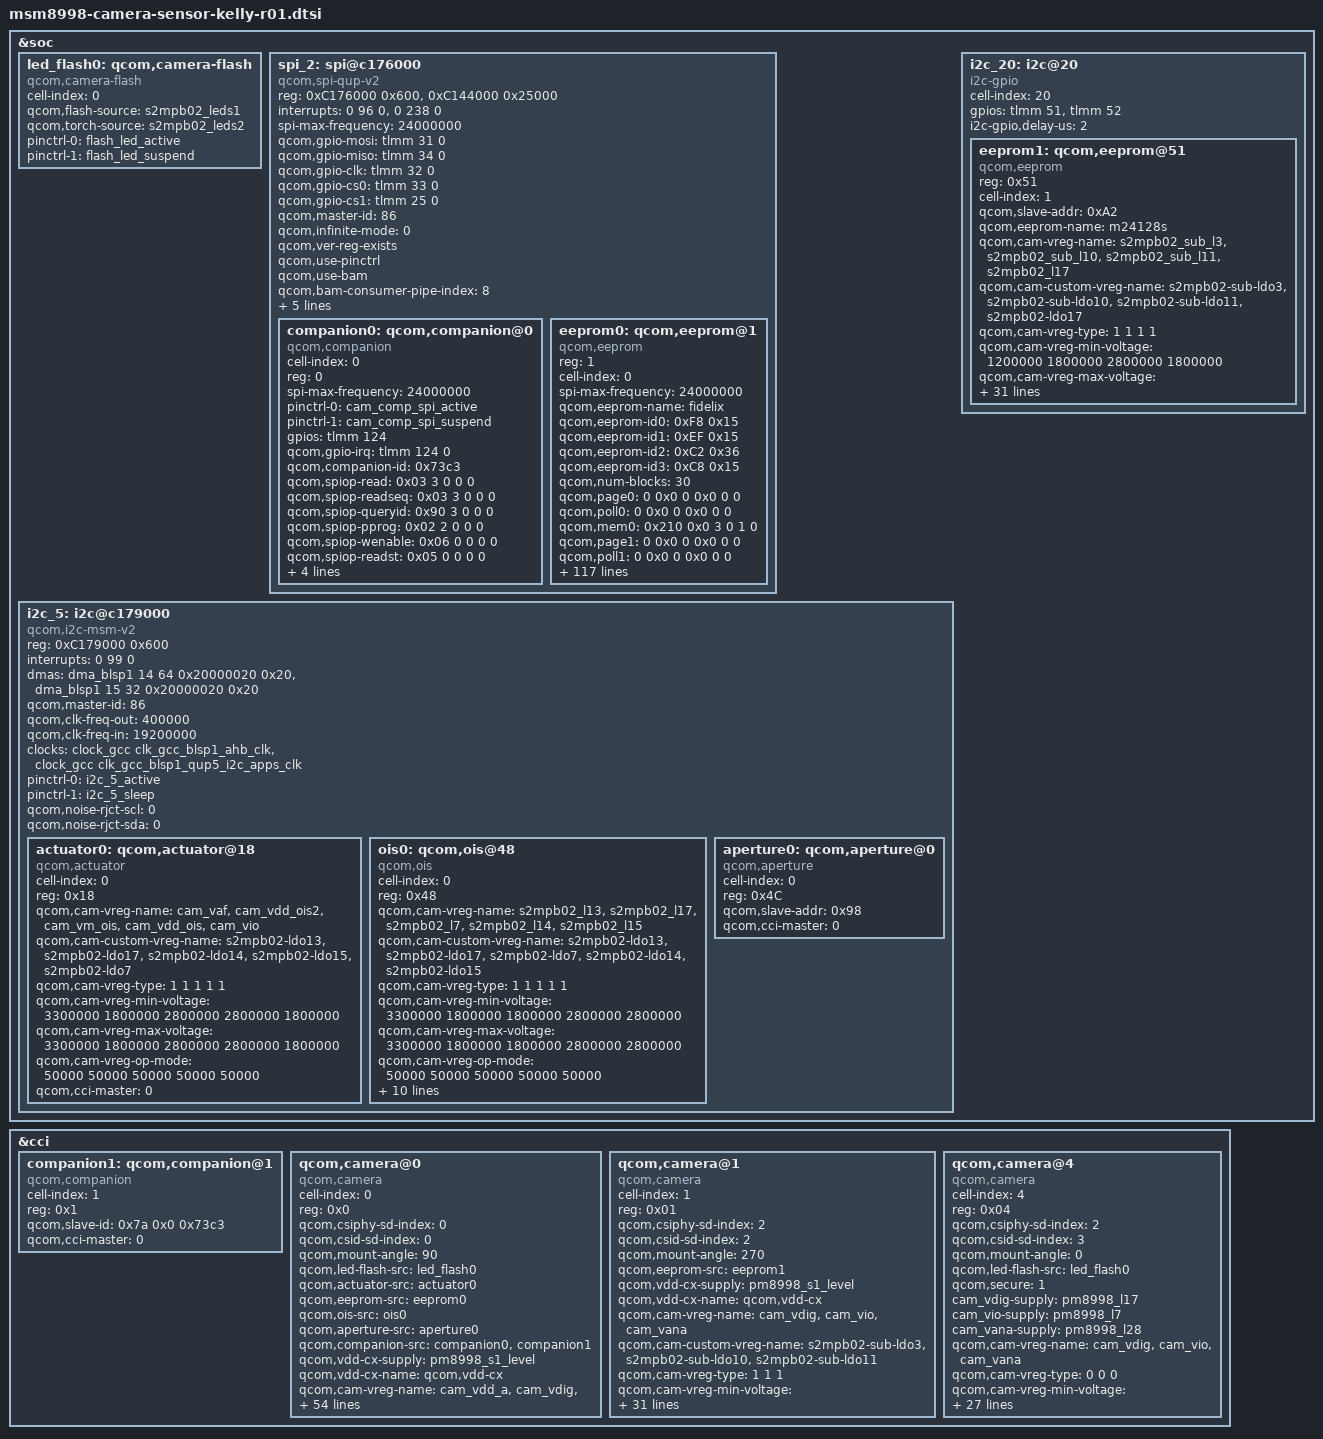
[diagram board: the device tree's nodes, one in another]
/*
 * Copyright (c) 2015 The Linux Foundation. All rights reserved.
 *
 * This program is free software; you can redistribute it and/or modify
 * it under the terms of the GNU General Public License version 2 and
 * only version 2 as published by the Free Software Foundation.
 *
 * This program is distributed in the hope that it will be useful,
 * but WITHOUT ANY WARRANTY; without even the implied warranty of
 * MERCHANTABILITY or FITNESS FOR A PARTICULAR PURPOSE.  See the
 * GNU General Public License for more details.
 */

&soc {
	led_flash0: qcom,camera-flash {
		cell-index = <0>;
		compatible = "qcom,camera-flash";
		qcom,flash-source = <&s2mpb02_leds1>;
		qcom,torch-source = <&s2mpb02_leds2>;
		pinctrl-names = "flash_default", "flash_suspend";
		pinctrl-0 = <&flash_led_active>;
		pinctrl-1 = <&flash_led_suspend>;
	};
};

&soc {
	spi_2: spi@c176000 {
		compatible = "qcom,spi-qup-v2";

		reg-names = "spi_physical", "spi_bam_physical";
		reg = <0xC176000 0x600>, <0xC144000 0x25000>;
		interrupt-names = "spi_irq", "spi_bam_irq";
		interrupts = <0 96 0>, <0 238 0>;

		spi-max-frequency = <24000000>;
		#address-cells = <1>;
		#size-cells = <0>;

		qcom,gpio-mosi = <&tlmm 31 0>;
		qcom,gpio-miso = <&tlmm 34 0>;
		qcom,gpio-clk  = <&tlmm 32 0>;
		qcom,gpio-cs0  = <&tlmm 33 0>;
		qcom,gpio-cs1  = <&tlmm 25 0>;

		qcom,master-id = <86>;
		qcom,infinite-mode = <0>;
		qcom,ver-reg-exists;
		qcom,use-pinctrl;
		qcom,use-bam;
		qcom,bam-consumer-pipe-index = <8>;
		qcom,bam-producer-pipe-index = <9>;
		pinctrl-names = "spi_default", "spi_sleep";
		pinctrl-0 = <&spi_2_active &spi_2_cs1_active>;
		pinctrl-1 = <&spi_2_sleep &spi_2_cs1_sleep>;
		status = "ok";

		clock-names = "iface_clk", "core_clk";

		clocks = <&clock_gcc clk_gcc_blsp1_ahb_clk>,
			 <&clock_gcc clk_gcc_blsp1_qup2_spi_apps_clk>;
	};

	i2c_5: i2c@c179000 {
		compatible = "qcom,i2c-msm-v2";
		#address-cells = <1>;
		#size-cells = <0>;
		reg-names = "qup_phys_addr";
		reg = <0xC179000 0x600>;
		interrupt-names = "qup_irq";
		interrupts = <0 99 0>;
		dmas = <&dma_blsp1 14 64 0x20000020 0x20>,
			<&dma_blsp1 15 32 0x20000020 0x20>;
		dma-names = "tx", "rx";
		qcom,master-id = <86>;
		qcom,clk-freq-out = <400000>;
		qcom,clk-freq-in  = <19200000>;
		clock-names = "iface_clk", "core_clk";
		clocks = <&clock_gcc clk_gcc_blsp1_ahb_clk>,
			<&clock_gcc clk_gcc_blsp1_qup5_i2c_apps_clk>;
		pinctrl-names = "i2c_active", "i2c_sleep";
		pinctrl-0 = <&i2c_5_active>;
		pinctrl-1 = <&i2c_5_sleep>;
		qcom,noise-rjct-scl = <0>;
		qcom,noise-rjct-sda = <0>;
		status = "ok";
	};

};

&i2c_5 {
	actuator0: qcom,actuator@18 {
		compatible = "qcom,actuator";
		cell-index = <0>;
		reg = <0x18>;
		qcom,cam-vreg-name = "cam_vaf", "cam_vdd_ois2", "cam_vm_ois", "cam_vdd_ois", "cam_vio";
		qcom,cam-custom-vreg-name = "s2mpb02-ldo13", "s2mpb02-ldo17", "s2mpb02-ldo14", "s2mpb02-ldo15", "s2mpb02-ldo7";
		qcom,cam-vreg-type = <1 1 1 1 1>;
		qcom,cam-vreg-min-voltage = <3300000 1800000 2800000 2800000 1800000>;
		qcom,cam-vreg-max-voltage = <3300000 1800000 2800000 2800000 1800000>;
		qcom,cam-vreg-op-mode = <50000 50000 50000 50000 50000>;
		qcom,cci-master = <0>;
		status = "ok";
	};

	ois0: qcom,ois@48  {
		compatible = "qcom,ois";
		cell-index = <0>;
		reg = <0x48>;
		qcom,cam-vreg-name = "s2mpb02_l13", "s2mpb02_l17", "s2mpb02_l7", "s2mpb02_l14", "s2mpb02_l15";
		qcom,cam-custom-vreg-name = "s2mpb02-ldo13", "s2mpb02-ldo17","s2mpb02-ldo7", "s2mpb02-ldo14", "s2mpb02-ldo15";
		qcom,cam-vreg-type = <1 1 1 1 1>;
		qcom,cam-vreg-min-voltage = <3300000 1800000 1800000 2800000 2800000>;
		qcom,cam-vreg-max-voltage = <3300000 1800000 1800000 2800000 2800000>;
		qcom,cam-vreg-op-mode = <50000 50000 50000 50000 50000>;
		qcom,cci-master = <0>;
		gpios = <&tlmm 30 0>; /* RESET */
		qcom,gpio-reset = <0>;
		qcom,gpio-req-tbl-num = <0>;
		qcom,gpio-req-tbl-flags = <0>;
		qcom,gpio-req-tbl-label = "CAM_RESET0";
		qcom,gpio-set-tbl-delay = <1000>;
               clocks = <&clock_mmss clk_mclk0_clk_src>,
			<&clock_mmss clk_mmss_camss_mclk0_clk>;
		clock-names = "cam_src_clk", "cam_clk";
		qcom,clock-rates = <24000000 0>;
		status = "ok";
	};

	aperture0: qcom,aperture@0 {
		compatible = "qcom,aperture";
		cell-index = <0>;
		reg = <0x4C>;
		qcom,slave-addr = <0x98>;
		qcom,cci-master = <0>;
		status = "ok";
	};
};

&soc {
	i2c_20: i2c@20 {
		cell-index = <20>;
		compatible = "i2c-gpio";
		gpios = <&tlmm 51 0 // SDA
			&tlmm 52 0 // SCL
			>;
		i2c-gpio,delay-us = <2>;
		#address-cells = <1>;
		#size-cells = <0>;

		eeprom1: qcom,eeprom@51 {
			compatible = "qcom,eeprom";
			reg = <0x51>;
			cell-index = <1>;
			qcom,slave-addr = <0xA2>;
			qcom,eeprom-name = "m24128s";
			qcom,cam-vreg-name = "s2mpb02_sub_l3", "s2mpb02_sub_l10", "s2mpb02_sub_l11", "s2mpb02_l17";
			qcom,cam-custom-vreg-name = "s2mpb02-sub-ldo3", "s2mpb02-sub-ldo10", "s2mpb02-sub-ldo11", "s2mpb02-ldo17";
			qcom,cam-vreg-type = <1 1 1 1>;
			qcom,cam-vreg-min-voltage = <1200000 1800000 2800000 1800000>;
			qcom,cam-vreg-max-voltage = <1200000 1800000 2800000 1800000>;
			qcom,cam-vreg-op-mode = <200000 200000 200000 200000>;
			qcom,cam-power-seq-type = "sensor_vreg", "sensor_vreg", "sensor_vreg", "sensor_vreg";
			qcom,cam-power-seq-val = "s2mpb02_sub_l3", "s2mpb02_sub_l10", "s2mpb02_sub_l11", "s2mpb02_l17";
			qcom,cam-power-seq-cfg-val = <1 1 1 1>;
			qcom,cam-power-seq-delay =   <0 0 0 0>;
			qcom,sensor-position = <1>;
			qcom,num-blocks = <6>;
			qcom,page0 = <0 0x0 0 0x0 0 0>;
			qcom,poll0 = <0 0x0 0 0x0 0 0>;
			qcom,mem0 = <0xC0 0x0 2 0 1 0>;
			qcom,page1 = <0 0x0 0 0x0 0 0>;
			qcom,poll1 = <0 0x0 0 0x0 0 0>;
			qcom,mem1 = <0x4 0xFC 2 0 1 0>;
			qcom,page2 = <0 0x0 0 0x0 0 0>;
			qcom,poll2 = <0 0x0 0 0x0 0 0>;
			qcom,mem2 = <0x20 0x200 2 0 1 0>;
			qcom,page3 = <0 0x0 0 0x0 0 0>;
			qcom,poll3 = <0 0x0 0 0x0 0 0>;
			qcom,mem3 = <0x4 0x2FC 2 0 1 0>;
			qcom,page4 = <0 0x0 0 0x0 0 0>;
			qcom,poll4 = <0 0x0 0 0x0 0 0>;
			qcom,mem4 = <0x700 0x300 2 0 1 0>;
			qcom,page5 = <0 0x0 0 0x0 0 0>;
			qcom,poll5 = <0 0x0 0 0x0 0 0>;
			qcom,mem5 = <0x4 0xAFC 2 0 1 0>;
			qcom,total-size = <0xB00>;
			status = "ok";
		};
	};
};

&spi_2 {
	companion0: qcom,companion@0 {
		compatible = "qcom,companion";
		cell-index = <0>;
		reg = <0>;
		spi-max-frequency = <24000000>;
		pinctrl-names = "cam_default", "cam_suspend";
		pinctrl-0 = <&cam_comp_spi_active>;
		pinctrl-1 = <&cam_comp_spi_suspend>;
		status = "ok";
		gpios = <&tlmm 124 0>; /* COMP_PAF_INT */
		qcom,gpio-irq = <&tlmm 124 0>;
		qcom,companion-id = <0x73c3>;
		qcom,spiop-read = <0x03 3 0 0 0>;
		qcom,spiop-readseq = <0x03 3 0 0 0>;
		qcom,spiop-queryid = <0x90 3 0 0 0>;
		qcom,spiop-pprog = <0x02 2 0 0 0>;
		qcom,spiop-wenable = <0x06 0 0 0 0>;
		qcom,spiop-readst = <0x05 0 0 0 0>;
		qcom,spiop-erase = <0x20 2 0 10 30>;
		qcom,spi-busy-mask = <0x01>;
		qcom,spi-page-size = <0x256>;
		qcom,spi-erase-size = <0x4096>;
	};

	eeprom0: qcom,eeprom@1 {
		compatible = "qcom,eeprom";
		reg = <1>;
		cell-index = <0>;
		spi-max-frequency = <24000000>;
		status = "ok";

		qcom,eeprom-name = "fidelix";
		qcom,eeprom-id0 = <0xF8 0x15>;
		qcom,eeprom-id1 = <0xEF 0x15>;
		qcom,eeprom-id2 = <0xC2 0x36>;
		qcom,eeprom-id3 = <0xC8 0x15>;

		qcom,num-blocks = <30>;
		qcom,page0 = <0 0x0 0 0x0 0 0>;
		qcom,poll0 = <0 0x0 0 0x0 0 0>;
		qcom,mem0 = <0x210 0x0 3 0 1 0>;
		qcom,page1 = <0 0x0 0 0x0 0 0>;
		qcom,poll1 = <0 0x0 0 0x0 0 0>;
		qcom,mem1 = <0x4 0xFFC 3 0 1 0>;
		qcom,page2 = <0 0x0 0 0x0 0 0>;
		qcom,poll2 = <0 0x0 0 0x0 0 0>;
		qcom,mem2 = <0x16F8 0x1006 3 0 0 0>;
		qcom,page3 = <0 0x0 0 0x0 0 0>;
		qcom,poll3 = <0 0x0 0 0x0 0 0>;
		qcom,mem3 = <0x4 0x26FE 3 0 0 0>;
		qcom,page4 = <0 0x0 0 0x0 0 0>;
		qcom,poll4 = <0 0x0 0 0x0 0 0>;
		qcom,mem4 = <0xE4 0x2702 3 0 0 0>;
		qcom,page5 = <0 0x0 0 0x0 0 0>;
		qcom,poll5 = <0 0x0 0 0x0 0 0>;
		qcom,mem5 = <0x4 0x27E6 3 0 0 0>;
		qcom,page6 = <0 0x0 0 0x0 0 0>;
		qcom,poll6 = <0 0x0 0 0x0 0 0>;
		qcom,mem6 = <0x1000 0x27F0 3 0 0 0>;
		qcom,page7 = <0 0x0 0 0x0 0 0>;
		qcom,poll7 = <0 0x0 0 0x0 0 0>;
		qcom,mem7 = <0x4 0x37F0 3 0 0 0>;
		qcom,page8 = <0 0x0 0 0x0 0 0>;
		qcom,poll8 = <0 0x0 0 0x0 0 0>;
		qcom,mem8 = <0x420 0x37F4 3 0 0 0>;
		qcom,page9 = <0 0x0 0 0x0 0 0>;
		qcom,poll9 = <0 0x0 0 0x0 0 0>;
		qcom,mem9 = <0x4 0x3C14 3 0 0 0>;
		qcom,page10 = <0 0x0 0 0x0 0 0>;
		qcom,poll10 = <0 0x0 0 0x0 0 0>;
		qcom,mem10 = <0x16F8 0x3C26 3 0 0 0>;
		qcom,page11 = <0 0x0 0 0x0 0 0>;
		qcom,poll11 = <0 0x0 0 0x0 0 0>;
		qcom,mem11 = <0x4 0x531E 3 0 0 0>;
		qcom,page12 = <0 0x0 0 0x0 0 0>;
		qcom,poll12 = <0 0x0 0 0x0 0 0>;
		qcom,mem12 = <0xE4 0x5322 3 0 0 0>;
		qcom,page13 = <0 0x0 0 0x0 0 0>;
		qcom,poll13 = <0 0x0 0 0x0 0 0>;
		qcom,mem13 = <0x4 0x5406 3 0 0 0>;
		qcom,page14 = <0 0x0 0 0x0 0 0>;
		qcom,poll14 = <0 0x0 0 0x0 0 0>;
		qcom,mem14 = <0x1000 0x5410 3 0 0 0>;
		qcom,page15 = <0 0x0 0 0x0 0 0>;
		qcom,poll15 = <0 0x0 0 0x0 0 0>;
		qcom,mem15 = <0x4 0x6410 3 0 0 0>;
		qcom,page16 = <0 0x0 0 0x0 0 0>;
		qcom,poll16 = <0 0x0 0 0x0 0 0>;
		qcom,mem16 = <0x420 0x6414 3 0 0 0>;
		qcom,page17 = <0 0x0 0 0x0 0 0>;
		qcom,poll17 = <0 0x0 0 0x0 0 0>;
		qcom,mem17 = <0x4 0x6834 3 0 0 0>;
		qcom,page18 = <0 0x0 0 0x0 0 0>;
		qcom,poll18 = <0 0x0 0 0x0 0 0>;
		qcom,mem18 = <0x2C 0x6840 3 0 0 0>;
		qcom,page19 = <0 0x0 0 0x0 0 0>;
		qcom,poll19 = <0 0x0 0 0x0 0 0>;
		qcom,mem19 = <0x4 0x686C 3 0 0 0>;
		qcom,page20 = <0 0x0 0 0x0 0 0>;
		qcom,poll20 = <0 0x0 0 0x0 0 0>;
		qcom,mem20 = <0x7C 0x6870 3 0 0 0>;
		qcom,page21 = <0 0x0 0 0x0 0 0>;
		qcom,poll21 = <0 0x0 0 0x0 0 0>;
		qcom,mem21 = <0x4 0x68EC 3 0 0 0>;
		qcom,page22 = <0 0x0 0 0x0 0 0>;
		qcom,poll22 = <0 0x0 0 0x0 0 0>;
		qcom,mem22 = <0x6C 0x68F0 3 0 0 0>;
		qcom,page23 = <0 0x0 0 0x0 0 0>;
		qcom,poll23 = <0 0x0 0 0x0 0 0>;
		qcom,mem23 = <0x4 0x695C 3 0 0 0>;
		qcom,page24 = <0 0x0 0 0x0 0 0>;
		qcom,poll24 = <0 0x0 0 0x0 0 0>;
		qcom,mem24 = <0x45C 0x6960 3 0 0 0>;
		qcom,page25 = <0 0x0 0 0x0 0 0>;
		qcom,poll25 = <0 0x0 0 0x0 0 0>;
		qcom,mem25 = <0x4 0x6DBC 3 0 0 0>;
		qcom,page26 = <0 0x0 0 0x0 0 0>;
		qcom,poll26 = <0 0x0 0 0x0 0 0>;
		qcom,mem26 = <0x45C 0x6DC0 3 0 0 0>;
		qcom,page27 = <0 0x0 0 0x0 0 0>;
		qcom,poll27 = <0 0x0 0 0x0 0 0>;
		qcom,mem27 = <0x4 0x721C 3 0 0 0>;
		qcom,page28 = <0 0x0 0 0x0 0 0>;
		qcom,poll28 = <0 0x0 0 0x0 0 0>;
		qcom,mem28 = <0x6220 0x1000 3 0 1 0>;
		qcom,page29 = <0 0x0 0 0x0 0 0>;
		qcom,poll29 = <0 0x0 0 0x0 0 0>;
		qcom,mem29 = <0x4 0x7FFC 3 0 1 0>;
		qcom,total-size = <0x8000>;

		qcom,cam-vreg-name = "s2mpb02_l13", "s2mpb02_l17", "s2mpb02_l14", "s2mpb02_l15", "s2mpb02_l7";
		qcom,cam-custom-vreg-name = "s2mpb02-ldo13", "s2mpb02-ldo17", "s2mpb02-ldo14", "s2mpb02-ldo15", "s2mpb02-ldo7";
		qcom,cam-vreg-type = <1 1 1 1 1>;
		qcom,cam-vreg-min-voltage = <3300000 1800000 2800000 2800000 1800000>;
		qcom,cam-vreg-max-voltage = <3300000 1800000 2800000 2800000 1800000>;
		qcom,cam-vreg-op-mode = <50000 50000 50000 50000 50000>;
		qcom,cam-power-seq-type = "sensor_vreg", "sensor_vreg", "sensor_vreg", "sensor_vreg", "sensor_vreg";
		qcom,cam-power-seq-val = "s2mpb02_l13", "s2mpb02_l17", "s2mpb02_l14", "s2mpb02_l15", "s2mpb02_l7";
		qcom,cam-power-seq-cfg-val = <1 1 1 1 1>;
		qcom,cam-power-seq-delay = <0 0 0 0 0>;
		qcom,sensor-position = <0>;

		qcom,spiop-read = <0x03 3 0 0 0>;
		qcom,spiop-readseq = <0x03 3 0 0 0>;
		qcom,spiop-queryid = <0x90 3 0 0 0>;
		qcom,spiop-pprog = <0x02 3 0 3 100>;
		qcom,spiop-wenable = <0x06 0 0 0 0>;
		qcom,spiop-readst = <0x05 0 0 0 0>;
		qcom,spiop-erase = <0x20 3 0 10 100>;
		qcom,spi-busy-mask = <0x01>;
		qcom,spi-page-size = <256>;
		qcom,spi-erase-size = <4096>;
	};
};

&cci {
	companion1: qcom,companion@1  {
		cell-index = <1>;
		compatible = "qcom,companion";
		reg = <0x1>;
		qcom,slave-id = <0x7a 0x0 0x73c3>;
		qcom,cci-master = <0>;
		status = "ok";
	};

	qcom,camera@0 {
		cell-index = <0>;
		compatible = "qcom,camera";
		reg = <0x0>;
		qcom,csiphy-sd-index = <0>;
		qcom,csid-sd-index = <0>;
		qcom,mount-angle = <90>;
		qcom,led-flash-src = <&led_flash0>;
		qcom,actuator-src = <&actuator0>;
		qcom,eeprom-src = <&eeprom0>;
		qcom,ois-src = <&ois0>;
		qcom,aperture-src = <&aperture0>;
		qcom,companion-src = <&companion0 &companion1>;
		qcom,vdd-cx-supply = <&pm8998_s1_level>;
		qcom,vdd-cx-name = "qcom,vdd-cx";
		qcom,cam-vreg-name = "cam_vdd_a", "cam_vdig", "cam_vio", "cam_vaf", "cam_vana", "cam_vdd_ois2", "cam_vdd_ois", "cam_vm_ois", "cam_comp_mipi", "cam_comp_io", "cam_comp_vdig", "cam_comp_vnoret", "cam_comp_vana", "cam_comp_vret", "cam_comp_vret_retmode";
		qcom,cam-custom-vreg-name = "s2mpb02-ldo10", "s2mpb02-ldo3", "s2mpb02-ldo7", "s2mpb02-ldo13", "s2mpb02-ldo11", "s2mpb02-ldo17", "s2mpb02-ldo15", "s2mpb02-ldo14", "s2mpb02-ldo2", "s2mpb02-ldo8", "s2mpb02-buck2", "s2mpb02-ldo1", "s2mpb02-ldo9", "s2mpb02-ldo4", "s2mpb02-ldo4";
		qcom,cam-vreg-type = <1 1 1 1 1 1 1 1 1 1 1 1 1 1 1>;
		qcom,cam-vreg-min-voltage = <1800000 1050000 1800000 3300000 1200000 1800000 2800000 2800000 1000000 1800000 825000 950000 1800000 1050000 1050000>;
		qcom,cam-vreg-max-voltage = <1800000 1050000 1800000 3300000 2950000 1800000 2800000 2800000 1000000 1800000 825000 950000 1800000 1050000 1050000>;
		qcom,cam-vreg-op-mode = <5000 5000 5000 50000 50000 50000 50000 50000 5000 5000 50000 50000 50000 50000 50000>;
		qcom,gpio-no-mux = <0>;
		pinctrl-names = "cam_default", "cam_suspend";
		pinctrl-0 = <&cam_sensor_mclk0_active &cam_sensor_mclk1_active &cam_sensor_rear_active &cam_comp_spi_active>;
		pinctrl-1 = <&cam_sensor_mclk0_suspend &cam_sensor_mclk1_suspend &cam_sensor_rear_suspend &cam_comp_spi_suspend>;
		gpios = <&tlmm 13 0>, // MCLK
			<&tlmm 30 0>,// RESET
			<&tlmm 89 0>; // COMPANION_RSTN
		qcom,gpio-reset = <1>;
		qcom,gpio-comprstn = <2>;
		qcom,gpio-req-tbl-num = <0 1 2>;
		qcom,gpio-req-tbl-flags = <1 0 0>;
		qcom,gpio-req-tbl-label = "CAMIF_MCLK0", "CAM_RESET0",
                                           "CAM_COMPRSTN_GPIO";
		qcom,gpio-set-tbl-delay = <1000 30000>;
		qcom,gpio-comp-spi-irq = <&tlmm 124 0>;// COMP_SPI_INT
		qcom,sensor-position = <0>;
		qcom,sensor-mode = <0>;
		qcom,cci-master = <0>;
		status = "ok";
		clocks = <&clock_mmss clk_mclk0_clk_src>,
				<&clock_mmss clk_mmss_camss_mclk0_clk>,
				<&clock_mmss clk_mclk1_clk_src>,
				<&clock_mmss clk_mmss_camss_mclk1_clk>;
		clock-names = "cam_src_clk", "cam_clk", "cam_src_clk1", "cam_clk1";
		qcom,clock-rates = <24000000 0 24000000 0>;
		cam,isp = <0>;                  // 0 : INT , 1 : EXT , 2 : SOC
		cam,cal_memory = <1>;           // 0 : N , 1 : FROM , 2 : EEPROM , 3 : OTP
		cam,read_version = <1>;         // 0 : SYSFS , 1 : CAMON
		cam,core_voltage = <1>;         // 0 : N , 1 : Y
		cam,upgrade = <2>;              // 0 : N , 1 : SYSFS , 2 : CAMON
		cam,fw_write = <3>;             // 0 : N , 1 : OS , 2 : SD , 3 : ALL
		cam,fw_dump = <1>;              // 0 : N , 1 : Y
		cam,companion_chip = <1>;       // 0 : N , 1 : Y
		cam,ois = <1>;                  // 0 : N , 1 : Y
		cam,valid = <0>;                // 0 : N , 1 : Y
	};

	qcom,camera@1 {
		cell-index = <1>;
		compatible = "qcom,camera";
		reg = <0x01>;
		qcom,csiphy-sd-index = <2>;
		qcom,csid-sd-index = <2>;
		qcom,mount-angle = <270>;
		qcom,eeprom-src = <&eeprom1>;
		qcom,vdd-cx-supply = <&pm8998_s1_level>;
		qcom,vdd-cx-name = "qcom,vdd-cx";
		qcom,cam-vreg-name = "cam_vdig", "cam_vio", "cam_vana";
		qcom,cam-custom-vreg-name = "s2mpb02-sub-ldo3", "s2mpb02-sub-ldo10", "s2mpb02-sub-ldo11";
		qcom,cam-vreg-type = <1 1 1>;
		qcom,cam-vreg-min-voltage = <1200000 1800000 2800000>;
		qcom,cam-vreg-max-voltage = <1200000 1800000 2800000>;
		qcom,cam-vreg-op-mode = <200000 200000 200000>;
		qcom,gpio-no-mux = <0>;
		pinctrl-names = "cam_default", "cam_suspend";
		pinctrl-0 = <&cam_sensor_mclk2_active &cam_sensor_front_active>;
		pinctrl-1 = <&cam_sensor_mclk2_suspend &cam_sensor_front_suspend>;
		gpios = <&tlmm 15 0>, // MCLK
			<&tlmm 28 0>; // RESET
		qcom,gpio-reset = <1>;
		qcom,gpio-req-tbl-num = <0 1>;
		qcom,gpio-req-tbl-flags = <1 0>;
		qcom,gpio-req-tbl-label = "CAMIF_MCLK2",
					  "CAM_RESET2";
		qcom,sensor-position = <1>;
		qcom,sensor-mode = <0>;
		qcom,cci-master = <1>;
		status = "ok";
		clocks = <&clock_mmss clk_mclk2_clk_src>,
			<&clock_mmss clk_mmss_camss_mclk2_clk>;
		clock-names = "cam_src_clk", "cam_clk";
		qcom,clock-rates = <24000000 0>;
		cam,isp = <0>;                  // 0 : INT , 1 : EXT , 2 : SOC
		cam,cal_memory = <2>;           // 0 : N , 1 : FROM , 2 : EEPROM , 3 : OTP
		cam,read_version = <0>;         // 0 : SYSFS , 1 : CAMON
		cam,core_voltage = <0>;         // 0 : N , 1 : Y
		cam,upgrade = <0>;              // 0 : N , 1 : SYSFS , 2 : CAMON
		cam,fw_write = <0>;             // 0 : N , 1 : OS , 2 : SD , 3 : ALL
		cam,fw_dump = <0>;              // 0 : N , 1 : Y
		cam,companion_chip = <0>;       // 0 : N , 1 : Y
		cam,ois = <0>;                  // 0 : N , 1 : Y
		cam,valid = <0>;                // 0 : N , 1 : Y
	};

	qcom,camera@4 {
		cell-index = <4>;
		compatible = "qcom,camera";
		reg = <0x04>;
		qcom,csiphy-sd-index = <2>;
		qcom,csid-sd-index = <3>;
		qcom,mount-angle = <0>;
		qcom,led-flash-src = <&led_flash0>;
		/*qcom,vdd-cx-supply = <&pm8994_s1_corner>;
	  	  qcom,vdd-cx-name = "qcom,vdd-cx"; */
		qcom,secure = <1>;  /*Enable after TZ enable */
		cam_vdig-supply = <&pm8998_l17>;
		cam_vio-supply = <&pm8998_l7>;
		cam_vana-supply = <&pm8998_l28>;
		qcom,cam-vreg-name = "cam_vdig", "cam_vio", "cam_vana";
		qcom,cam-vreg-type = <0 0 0>;
		qcom,cam-vreg-min-voltage = <1200000 1800000 2800000>;
		qcom,cam-vreg-max-voltage = <1200000 1800000 2800000>;
		qcom,cam-vreg-op-mode = <200000 200000 200000>;
		qcom,gpio-no-mux = <0>;
		pinctrl-names = "cam_default", "cam_suspend";
		pinctrl-0 = <&cam_sensor_mclk3_active>;
		pinctrl-1 = <&cam_sensor_mclk3_suspend>;
		gpios = <&tlmm 16 0>; /* MCLK */
		qcom,gpio-req-tbl-num = <0>;
		qcom,gpio-req-tbl-flags = <1>;
		qcom,gpio-req-tbl-label = "CAMIF_MCLK3";
		qcom,sensor-position = <1>;
		qcom,sensor-mode = <0>;
		//qcom,cci-master = <1>;
		status = "ok";
		clocks = <&clock_mmss clk_mclk3_clk_src>,
			   <&clock_mmss clk_mmss_camss_mclk3_clk>;
		clock-names = "cam_src_clk", "cam_clk";
		qcom,clock-rates = <24000000 0>;
		cam,isp = <2>;                  // 0 : INT , 1 : EXT , 2 : SOC
		cam,cal_memory = <0>;           // 0 : N , 1 : FROM , 2 : EEPROM , 3 : OTP
		cam,read_version = <0>;         // 0 : SYSFS , 1 : CAMON
		cam,core_voltage = <0>;         // 0 : N , 1 : Y
		cam,upgrade = <0>;              // 0 : N , 1 : SYSFS , 2 : CAMON
		cam,fw_write = <0>;             // 0 : N , 1 : OS , 2 : SD , 3 : ALL
		cam,fw_dump = <0>;              // 0 : N , 1 : Y
		cam,companion_chip = <0>;       // 0 : N , 1 : Y
		cam,ois = <0>;                  // 0 : N , 1 : Y
		cam,dual_open = <0>;            // 0 : N , 1 : Y
		cam,valid = <1>;                // 0 : N , 1 : Y
	};
};
